# M2Sxxx register map
Vendor: Microsemi; Series: SmartFusion2; File version: 2.0.32
CPU: CM3 r2p1, little endian, MPU, no FPU, 4 interrupt priority bits
Registers are 32-bit, read-write, no defined reset value unless marked. A register's access mark holds for its fields unless they carry their own. Offsets are from the block's base; [hi:lo] are bit positions; {n}, {i} and the like mark numbered series; 'fields as' and 'values as' point back to an identical list.

## USB — No description provided for this peripheral
Base 0x40043000
0x00 USB_FADDR_REG 8-bit — No description provided for this register
  [6:0] FUNC_ADDR — No description provided for this field
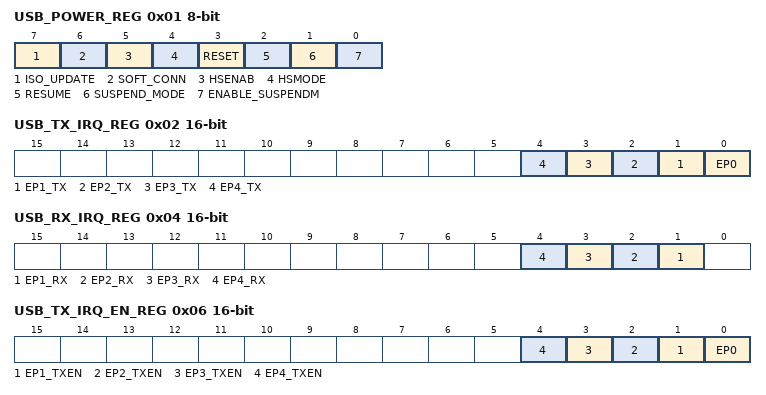
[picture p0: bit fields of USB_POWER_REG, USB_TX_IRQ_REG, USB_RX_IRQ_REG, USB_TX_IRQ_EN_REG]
0x01 USB_POWER_REG 8-bit — No description provided for this register
  [7] ISO_UPDATE ro — No description provided for this field
  [6] SOFT_CONN ro — No description provided for this field
  [5] HSENAB ro — No description provided for this field
  [4] HSMODE ro — No description provided for this field
  [3] RESET ro — No description provided for this field
  [2] RESUME ro — No description provided for this field
  [1] SUSPEND_MODE ro — No description provided for this field
  [0] ENABLE_SUSPENDM ro — No description provided for this field
0x02 USB_TX_IRQ_REG 16-bit — No description provided for this register
  [n] EP{n}_TX ro (n=1..4) — No description provided for this field
  [0] EP0 ro — No description provided for this field
0x04 USB_RX_IRQ_REG 16-bit — No description provided for this register
  [n] EP{n}_RX ro (n=1..4) — No description provided for this field
0x06 USB_TX_IRQ_EN_REG 16-bit — No description provided for this register
  [n] EP{n}_TXEN (n=1..4) — No description provided for this field
  [0] EP0 — No description provided for this field
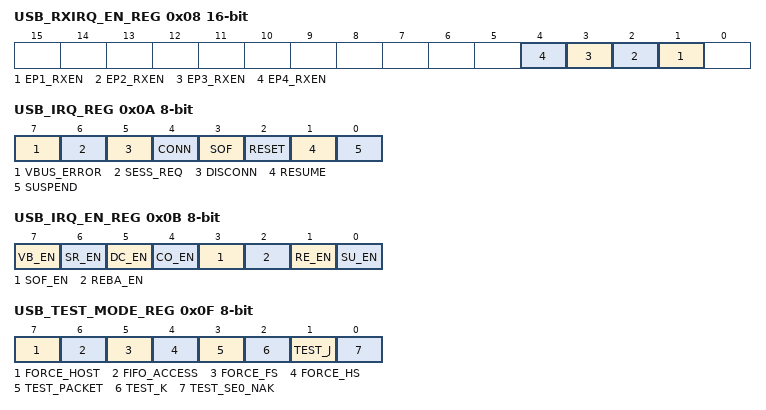
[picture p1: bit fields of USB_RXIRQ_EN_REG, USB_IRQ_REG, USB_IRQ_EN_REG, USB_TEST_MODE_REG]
0x08 USB_RXIRQ_EN_REG 16-bit — No description provided for this register
  [n] EP{n}_RXEN (n=1..4) — No description provided for this field
0x0A USB_IRQ_REG 8-bit — No description provided for this register
  [7] VBUS_ERROR ro — No description provided for this field
  [6] SESS_REQ ro — No description provided for this field
  [5] DISCONN ro — No description provided for this field
  [4] CONN ro — No description provided for this field
  [3] SOF ro — No description provided for this field
  [2] RESET ro — No description provided for this field
  [1] RESUME ro — No description provided for this field
  [0] SUSPEND ro — No description provided for this field
0x0B USB_IRQ_EN_REG 8-bit — No description provided for this register
  [7] VB_EN — No description provided for this field
  [6] SR_EN — No description provided for this field
  [5] DC_EN — No description provided for this field
  [4] CO_EN — No description provided for this field
  [3] SOF_EN — No description provided for this field
  [2] REBA_EN — No description provided for this field
  [1] RE_EN — No description provided for this field
  [0] SU_EN — No description provided for this field
0x0C USB_FRAME_REG 16-bit — No description provided for this register
  [10:0] FRAME_NUMBER ro — No description provided for this field
0x0E USB_INDEX_REG 8-bit — No description provided for this register
  [3:0] SEL_END_POINT — No description provided for this field
0x0F USB_TEST_MODE_REG 8-bit — No description provided for this register
  [7] FORCE_HOST — No description provided for this field
  [6] FIFO_ACCESS — No description provided for this field
  [5] FORCE_FS — No description provided for this field
  [4] FORCE_HS — No description provided for this field
  [3] TEST_PACKET — No description provided for this field
  [2] TEST_K — No description provided for this field
  [1] TEST_J — No description provided for this field
  [0] TEST_SE0_NAK — No description provided for this field
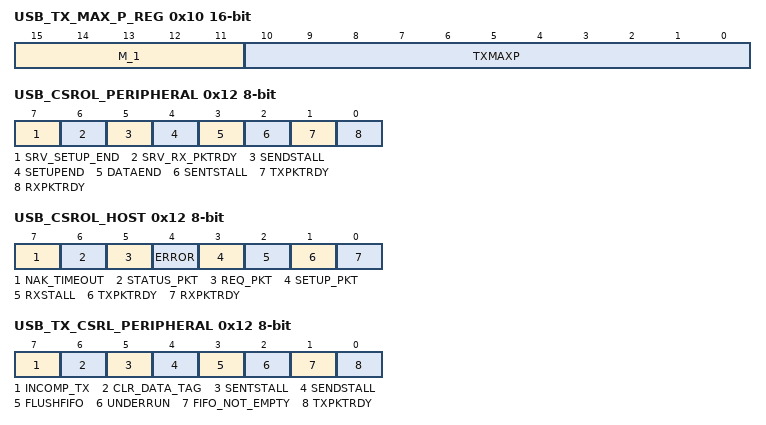
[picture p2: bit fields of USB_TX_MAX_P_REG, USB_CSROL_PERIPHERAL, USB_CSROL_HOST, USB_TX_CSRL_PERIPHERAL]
0x10 USB_TX_MAX_P_REG 16-bit — No description provided for this register
  [15:11] M_1 — No description provided for this field
  [10:0] TXMAXP — No description provided for this field
0x12 USB_CSROL_PERIPHERAL 8-bit — No description provided for this register
  [7] SRV_SETUP_END — No description provided for this field
  [6] SRV_RX_PKTRDY — No description provided for this field
  [5] SENDSTALL — No description provided for this field
  [4] SETUPEND — No description provided for this field
  [3] DATAEND — No description provided for this field
  [2] SENTSTALL — No description provided for this field
  [1] TXPKTRDY — No description provided for this field
  [0] RXPKTRDY — No description provided for this field
0x12 USB_CSROL_HOST 8-bit (alternate view of USB_CSROL_PERIPHERAL) — No description provided for this register
  [7] NAK_TIMEOUT — No description provided for this field
  [6] STATUS_PKT — No description provided for this field
  [5] REQ_PKT — No description provided for this field
  [4] ERROR — No description provided for this field
  [3] SETUP_PKT — No description provided for this field
  [2] RXSTALL — No description provided for this field
  [1] TXPKTRDY — No description provided for this field
  [0] RXPKTRDY — No description provided for this field
0x12 USB_TX_CSRL_PERIPHERAL 8-bit (alternate view of USB_CSROL_PERIPHERAL) — No description provided for this register
  [7] INCOMP_TX — No description provided for this field
  [6] CLR_DATA_TAG — No description provided for this field
  [5] SENTSTALL — No description provided for this field
  [4] SENDSTALL — No description provided for this field
  [3] FLUSHFIFO — No description provided for this field
  [2] UNDERRUN — No description provided for this field
  [1] FIFO_NOT_EMPTY — No description provided for this field
  [0] TXPKTRDY — No description provided for this field
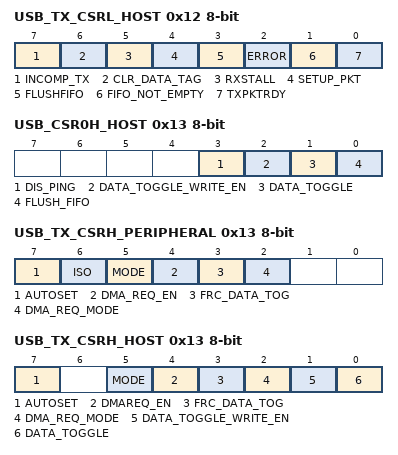
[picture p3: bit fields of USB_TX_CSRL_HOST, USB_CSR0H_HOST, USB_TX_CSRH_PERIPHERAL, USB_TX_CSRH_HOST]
0x12 USB_TX_CSRL_HOST 8-bit (alternate view of USB_CSROL_PERIPHERAL) — No description provided for this register
  [7] INCOMP_TX — No description provided for this field
  [6] CLR_DATA_TAG — No description provided for this field
  [5] RXSTALL — No description provided for this field
  [4] SETUP_PKT — No description provided for this field
  [3] FLUSHFIFO — No description provided for this field
  [2] ERROR — No description provided for this field
  [1] FIFO_NOT_EMPTY — No description provided for this field
  [0] TXPKTRDY — No description provided for this field
0x13 USB_CSR0H_HOST 8-bit — No description provided for this register
  [3] DIS_PING — No description provided for this field
  [2] DATA_TOGGLE_WRITE_EN — No description provided for this field
  [1] DATA_TOGGLE — No description provided for this field
  [0] FLUSH_FIFO — No description provided for this field
0x13 USB_CSROH_PERIPHERAL 8-bit (alternate view of USB_CSR0H_HOST) — No description provided for this register
  [0] FLUSH_FIFO — No description provided for this field
0x13 USB_TX_CSRH_PERIPHERAL 8-bit (alternate view of USB_CSR0H_HOST) — No description provided for this register
  [7] AUTOSET — No description provided for this field
  [6] ISO — No description provided for this field
  [5] MODE — No description provided for this field
  [4] DMA_REQ_EN — No description provided for this field
  [3] FRC_DATA_TOG — No description provided for this field
  [2] DMA_REQ_MODE — No description provided for this field
0x13 USB_TX_CSRH_HOST 8-bit (alternate view of USB_CSR0H_HOST) — No description provided for this register
  [7] AUTOSET — No description provided for this field
  [5] MODE — No description provided for this field
  [4] DMAREQ_EN — No description provided for this field
  [3] FRC_DATA_TOG — No description provided for this field
  [2] DMA_REQ_MODE — No description provided for this field
  [1] DATA_TOGGLE_WRITE_EN — No description provided for this field
  [0] DATA_TOGGLE — No description provided for this field
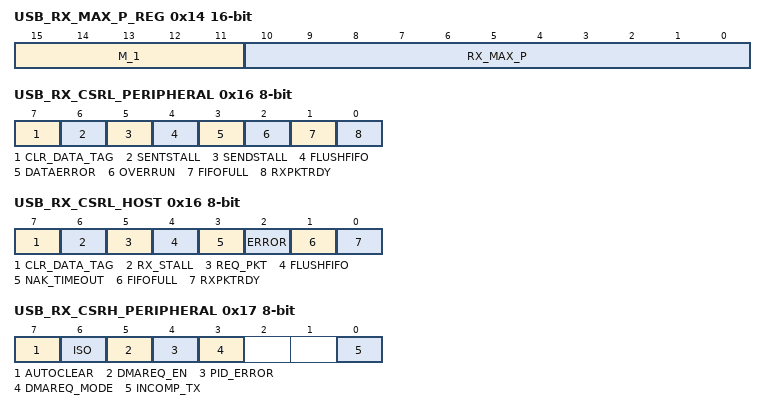
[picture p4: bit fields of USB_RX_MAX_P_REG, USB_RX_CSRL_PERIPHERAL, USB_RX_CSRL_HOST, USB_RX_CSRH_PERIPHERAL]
0x14 USB_RX_MAX_P_REG 16-bit — No description provided for this register
  [15:11] M_1 — No description provided for this field
  [10:0] RX_MAX_P — No description provided for this field
0x16 USB_RX_CSRL_PERIPHERAL 8-bit — No description provided for this register
  [7] CLR_DATA_TAG — No description provided for this field
  [6] SENTSTALL — No description provided for this field
  [5] SENDSTALL — No description provided for this field
  [4] FLUSHFIFO — No description provided for this field
  [3] DATAERROR — No description provided for this field
  [2] OVERRUN — No description provided for this field
  [1] FIFOFULL — No description provided for this field
  [0] RXPKTRDY — No description provided for this field
0x16 USB_RX_CSRL_HOST 8-bit (alternate view of USB_RX_CSRL_PERIPHERAL) — No description provided for this register
  [7] CLR_DATA_TAG — No description provided for this field
  [6] RX_STALL — No description provided for this field
  [5] REQ_PKT — No description provided for this field
  [4] FLUSHFIFO — No description provided for this field
  [3] NAK_TIMEOUT — No description provided for this field
  [2] ERROR — No description provided for this field
  [1] FIFOFULL — No description provided for this field
  [0] RXPKTRDY — No description provided for this field
0x17 USB_RX_CSRH_PERIPHERAL 8-bit — No description provided for this register
  [7] AUTOCLEAR — No description provided for this field
  [6] ISO — No description provided for this field
  [5] DMAREQ_EN — No description provided for this field
  [4] PID_ERROR — No description provided for this field
  [3] DMAREQ_MODE — No description provided for this field
  [0] INCOMP_TX — No description provided for this field
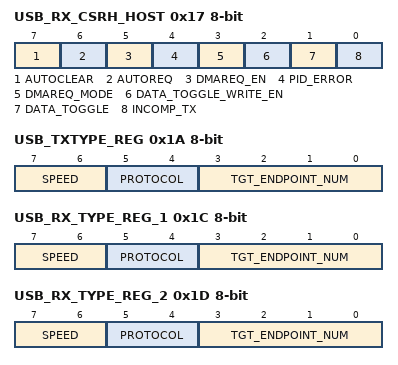
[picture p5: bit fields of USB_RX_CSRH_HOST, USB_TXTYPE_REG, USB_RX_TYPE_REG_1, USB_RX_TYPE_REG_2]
0x17 USB_RX_CSRH_HOST 8-bit (alternate view of USB_RX_CSRH_PERIPHERAL) — No description provided for this register
  [7] AUTOCLEAR — No description provided for this field
  [6] AUTOREQ — No description provided for this field
  [5] DMAREQ_EN — No description provided for this field
  [4] PID_ERROR — No description provided for this field
  [3] DMAREQ_MODE — No description provided for this field
  [2] DATA_TOGGLE_WRITE_EN — No description provided for this field
  [1] DATA_TOGGLE — No description provided for this field
  [0] INCOMP_TX — No description provided for this field
0x18 USB_RX_COUNT_REG 16-bit — No description provided for this register
  [13:0] ENDPOINT_RX_COUNT ro — No description provided for this field
0x18 USB_COUNT0_REG 8-bit (alternate view of USB_RX_COUNT_REG) — No description provided for this register
  [6:0] ENDPOINT_RX_COUNT ro — No description provided for this field
0x1A USB_TYPE0_REG 8-bit — No description provided for this register
  [7:6] SPEED — No description provided for this field
0x1A USB_TXTYPE_REG 8-bit (alternate view of USB_TYPE0_REG) — No description provided for this register
  [7:6] SPEED — No description provided for this field
  [5:4] PROTOCOL — No description provided for this field
  [3:0] TGT_ENDPOINT_NUM — No description provided for this field
0x1B USB_NAK_LIMIT0_REG 8-bit — No description provided for this register
  [4:0] ENDPOINT0_NAK_LIMIT — No description provided for this field
0x1B USB_TX_INTERVAL_REG 8-bit (alternate view of USB_NAK_LIMIT0_REG) — No description provided for this register
  [7:0] TX_INTERVAL — No description provided for this field
0x1C USB_RX_TYPE_REG_1 8-bit — No description provided for this register
  fields as USB_TXTYPE_REG
0x1D USB_RX_TYPE_REG_2 8-bit — No description provided for this register
  fields as USB_TXTYPE_REG
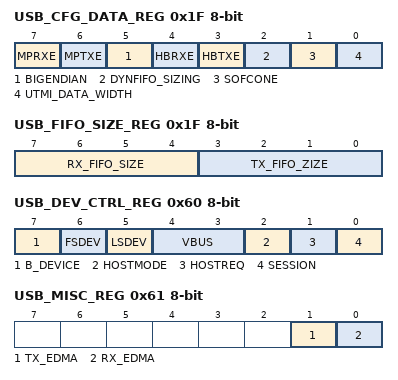
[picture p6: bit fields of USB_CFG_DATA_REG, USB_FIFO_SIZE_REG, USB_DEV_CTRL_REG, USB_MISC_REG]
0x1F USB_CFG_DATA_REG 8-bit — No description provided for this register
  [7] MPRXE ro — No description provided for this field
  [6] MPTXE ro — No description provided for this field
  [5] BIGENDIAN ro — No description provided for this field
  [4] HBRXE ro — No description provided for this field
  [3] HBTXE ro — No description provided for this field
  [2] DYNFIFO_SIZING ro — No description provided for this field
  [1] SOFCONE ro — No description provided for this field
  [0] UTMI_DATA_WIDTH ro — No description provided for this field
0x1F USB_FIFO_SIZE_REG 8-bit (alternate view of USB_CFG_DATA_REG) — No description provided for this register
  [7:4] RX_FIFO_SIZE ro — No description provided for this field
  [3:0] TX_FIFO_ZIZE ro — No description provided for this field
{0x20+4i} USB_EP{i}_FIFO_REG (i=0..4) — No description provided for this register
  [31:0] EP{i}_TXRXDATA_ACC — No description provided for this field
0x60 USB_DEV_CTRL_REG 8-bit — No description provided for this register
  [7] B_DEVICE ro — No description provided for this field
  [6] FSDEV ro — No description provided for this field
  [5] LSDEV ro — No description provided for this field
  [4:3] VBUS ro — No description provided for this field
  [2] HOSTMODE ro — No description provided for this field
  [1] HOSTREQ ro — No description provided for this field
  [0] SESSION ro — No description provided for this field
0x61 USB_MISC_REG 8-bit — No description provided for this register
  [1] TX_EDMA ro — No description provided for this field
  [0] RX_EDMA ro — No description provided for this field
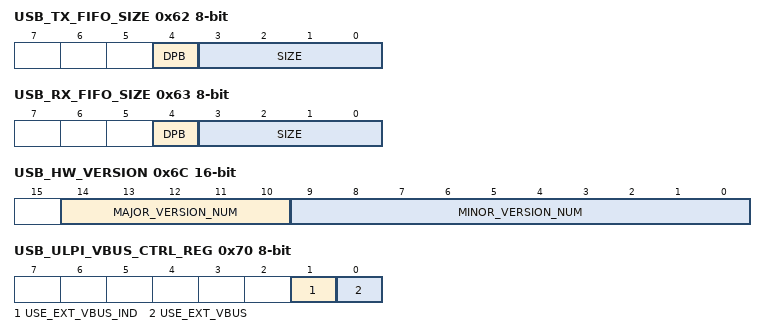
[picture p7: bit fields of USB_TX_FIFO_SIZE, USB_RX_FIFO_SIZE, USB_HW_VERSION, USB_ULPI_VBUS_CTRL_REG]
0x62 USB_TX_FIFO_SIZE 8-bit — No description provided for this register
  [4] DPB — No description provided for this field
  [3:0] SIZE — No description provided for this field
0x63 USB_RX_FIFO_SIZE 8-bit — No description provided for this register
  fields as USB_TX_FIFO_SIZE
0x64 USB_TX_FIFO_ADD_RANGE 16-bit — No description provided for this register
  [12:0] ADDRESS — No description provided for this field
0x66 USB_RX_FIFO_ADD_RANGE 16-bit — No description provided for this register
  [12:0] ADDRESS — No description provided for this field
0x68 USB_VBUS_CSR_REG 8-bit — No description provided for this register
  [3:0] VCONTROL — No description provided for this field
0x6C USB_HW_VERSION 16-bit — No description provided for this register
  [14:10] MAJOR_VERSION_NUM ro — No description provided for this field
  [9:0] MINOR_VERSION_NUM ro — No description provided for this field
0x70 USB_ULPI_VBUS_CTRL_REG 8-bit — No description provided for this register
  [1] USE_EXT_VBUS_IND ro — No description provided for this field
  [0] USE_EXT_VBUS ro — No description provided for this field
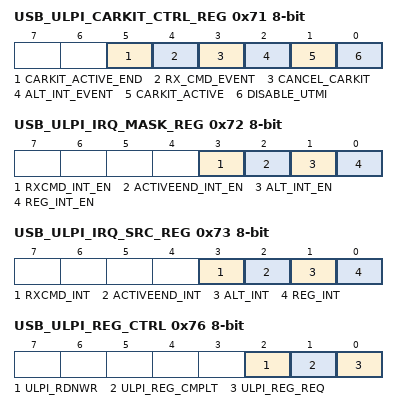
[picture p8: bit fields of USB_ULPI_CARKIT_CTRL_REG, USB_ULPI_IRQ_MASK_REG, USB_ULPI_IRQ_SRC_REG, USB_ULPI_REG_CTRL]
0x71 USB_ULPI_CARKIT_CTRL_REG 8-bit — No description provided for this register
  [5] CARKIT_ACTIVE_END ro — No description provided for this field
  [4] RX_CMD_EVENT ro — No description provided for this field
  [3] CANCEL_CARKIT ro — No description provided for this field
  [2] ALT_INT_EVENT ro — No description provided for this field
  [1] CARKIT_ACTIVE ro — No description provided for this field
  [0] DISABLE_UTMI ro — No description provided for this field
0x72 USB_ULPI_IRQ_MASK_REG 8-bit — No description provided for this register
  [3] RXCMD_INT_EN ro — No description provided for this field
  [2] ACTIVEEND_INT_EN ro — No description provided for this field
  [1] ALT_INT_EN ro — No description provided for this field
  [0] REG_INT_EN ro — No description provided for this field
0x73 USB_ULPI_IRQ_SRC_REG 8-bit — No description provided for this register
  [3] RXCMD_INT ro — No description provided for this field
  [2] ACTIVEEND_INT ro — No description provided for this field
  [1] ALT_INT ro — No description provided for this field
  [0] REG_INT ro — No description provided for this field
0x74 USB_ULPI_DATA_REG 8-bit — No description provided for this register
  [7:0] ULPI_REG_DATA ro — No description provided for this field
0x75 USB_ULPI_ADDR_RANGE 8-bit — No description provided for this register
  [7:0] ULPI_REG_ADDR ro — No description provided for this field
0x76 USB_ULPI_REG_CTRL 8-bit — No description provided for this register
  [2] ULPI_RDNWR ro — No description provided for this field
  [1] ULPI_REG_CMPLT ro — No description provided for this field
  [0] ULPI_REG_REQ ro — No description provided for this field
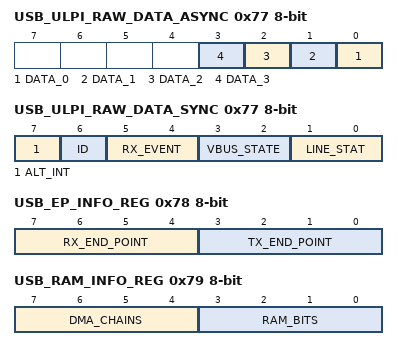
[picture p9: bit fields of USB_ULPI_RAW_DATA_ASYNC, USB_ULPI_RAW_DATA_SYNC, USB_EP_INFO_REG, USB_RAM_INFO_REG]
0x77 USB_ULPI_RAW_DATA_ASYNC 8-bit — No description provided for this register
  [n] DATA_{n} ro (n=0..3) — No description provided for this field
0x77 USB_ULPI_RAW_DATA_SYNC 8-bit (alternate view of USB_ULPI_RAW_DATA_ASYNC) — No description provided for this register
  [7] ALT_INT ro — No description provided for this field
  [6] ID ro — No description provided for this field
  [5:4] RX_EVENT ro — No description provided for this field
  [3:2] VBUS_STATE ro — No description provided for this field
  [1:0] LINE_STAT ro — No description provided for this field
0x78 USB_EP_INFO_REG 8-bit — No description provided for this register
  [7:4] RX_END_POINT ro — No description provided for this field
  [3:0] TX_END_POINT ro — No description provided for this field
0x79 USB_RAM_INFO_REG 8-bit — No description provided for this register
  [7:4] DMA_CHAINS ro — No description provided for this field
  [3:0] RAM_BITS ro — No description provided for this field
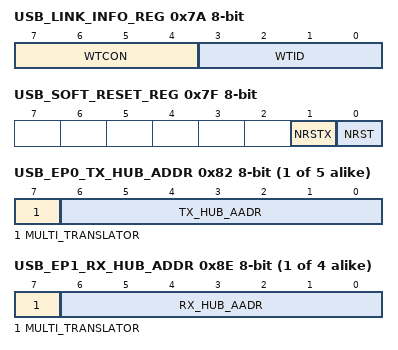
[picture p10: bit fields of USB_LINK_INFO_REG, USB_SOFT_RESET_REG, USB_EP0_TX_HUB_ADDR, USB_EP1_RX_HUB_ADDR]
0x7A USB_LINK_INFO_REG 8-bit — No description provided for this register
  [7:4] WTCON — No description provided for this field
  [3:0] WTID — No description provided for this field
0x7B USB_VP_LEN_REG 8-bit — No description provided for this register
  [7:0] VPLEN — No description provided for this field
0x7C USB_HS_EOF1_REG 8-bit — No description provided for this register
  [7:0] HS_EOF1 — No description provided for this field
0x7D USB_FS_EOF1_REG 8-bit — No description provided for this register
  [7:0] FS_EOF1 — No description provided for this field
0x7E USB_LS_EOF1_REG 8-bit — No description provided for this register
  [7:0] LS_EOF1 — No description provided for this field
0x7F USB_SOFT_RESET_REG 8-bit — No description provided for this register
  [1] NRSTX — No description provided for this field
  [0] NRST — No description provided for this field
{0x80+8i} USB_EP{i}_TX_FUNC_ADDR 8-bit (i=0..4) — No description provided for this register
  [6:0] TX_FUNC_ADDR — No description provided for this field
{0x82+8i} USB_EP{i}_TX_HUB_ADDR 8-bit (i=0..4) — No description provided for this register
  [7] MULTI_TRANSLATOR — No description provided for this field
  [6:0] TX_HUB_AADR — No description provided for this field
{0x83+8i} USB_EP{i}_TX_HUB_PORT 8-bit (i=0..4) — No description provided for this register
  [6:0] TX_HUB_PORT — No description provided for this field
{0x86+8i} USB_EP{i}_RX_HUB_ADDR 8-bit (i=1..4) — No description provided for this register
  [7] MULTI_TRANSLATOR — No description provided for this field
  [6:0] RX_HUB_AADR — No description provided for this field
{0x87+8i} USB_EP{i}_RX_HUB_PORT 8-bit (i=1..4) — No description provided for this register
  [6:0] RX_HUB_PORT — No description provided for this field
{0x84+8i} USB_EP{i}_RX_FUNC_ADDR 8-bit (i=2..4) — No description provided for this register
  [6:0] RX_FUNC_ADDR — No description provided for this field
0x100 USB_EP0_TX_MAX_P 16-bit — No description provided for this register
  [10:0] EP0_TX_MAP — No description provided for this field
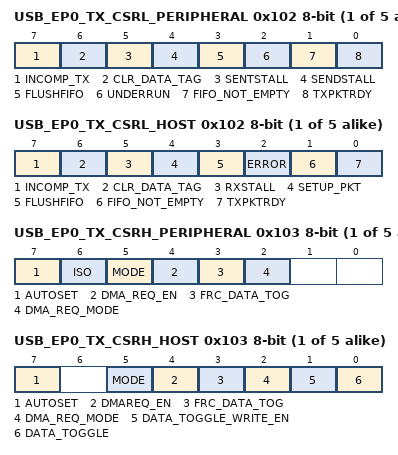
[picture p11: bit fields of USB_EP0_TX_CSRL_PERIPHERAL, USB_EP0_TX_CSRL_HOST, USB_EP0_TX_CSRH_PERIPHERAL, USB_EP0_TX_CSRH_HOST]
{0x102+0x10*i} USB_EP{i}_TX_CSRL_PERIPHERAL 8-bit (i=0..4) — No description provided for this register
  fields as USB_TX_CSRL_PERIPHERAL
{0x102+0x10*i} USB_EP{i}_TX_CSRL_HOST 8-bit (alternate view of USB_EP{i}_TX_CSRL_PERIPHERAL) (i=0..4) — No description provided for this register
  fields as USB_TX_CSRL_HOST
{0x103+0x10*i} USB_EP{i}_TX_CSRH_PERIPHERAL 8-bit (i=0..4) — No description provided for this register
  fields as USB_TX_CSRH_PERIPHERAL
{0x103+0x10*i} USB_EP{i}_TX_CSRH_HOST 8-bit (alternate view of USB_EP{i}_TX_CSRH_PERIPHERAL) (i=0..4) — No description provided for this register
  fields as USB_TX_CSRH_HOST
{0x104+0x10*i} USB_EP{i}_RX_MAX_P 16-bit (i=0..4) — No description provided for this register
  [10:0] EP{i}_RX_MAX_P — No description provided for this field
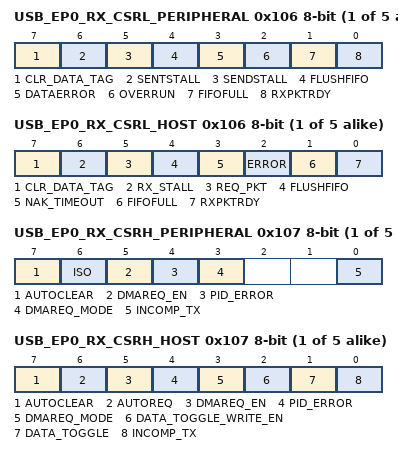
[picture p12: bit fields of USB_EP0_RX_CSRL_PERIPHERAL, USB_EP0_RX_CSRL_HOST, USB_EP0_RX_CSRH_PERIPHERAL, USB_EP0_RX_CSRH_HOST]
{0x106+0x10*i} USB_EP{i}_RX_CSRL_PERIPHERAL 8-bit (i=0..4) — No description provided for this register
  fields as USB_RX_CSRL_PERIPHERAL
{0x106+0x10*i} USB_EP{i}_RX_CSRL_HOST 8-bit (alternate view of USB_EP{i}_RX_CSRL_PERIPHERAL) (i=0..4) — No description provided for this register
  fields as USB_RX_CSRL_HOST
{0x107+0x10*i} USB_EP{i}_RX_CSRH_PERIPHERAL 8-bit (i=0..4) — No description provided for this register
  fields as USB_RX_CSRH_PERIPHERAL
{0x107+0x10*i} USB_EP{i}_RX_CSRH_HOST 8-bit (alternate view of USB_EP{i}_RX_CSRH_PERIPHERAL) (i=0..4) — No description provided for this register
  fields as USB_RX_CSRH_HOST
{0x108+0x10*i} USB_EP{i}_RX_COUNT 16-bit (i=0..4) — No description provided for this register
  [13:0] EP{i}_RX_COUNT ro — No description provided for this field
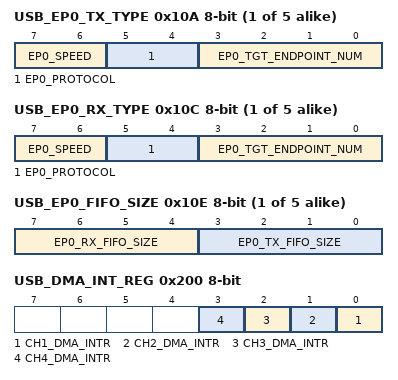
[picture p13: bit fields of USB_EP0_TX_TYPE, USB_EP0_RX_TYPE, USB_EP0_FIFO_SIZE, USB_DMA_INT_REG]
{0x10A+0x10*i} USB_EP{i}_TX_TYPE 8-bit (i=0..4) — No description provided for this register
  [7:6] EP{i}_SPEED wo — No description provided for this field
  [5:4] EP{i}_PROTOCOL wo — No description provided for this field
  [3:0] EP{i}_TGT_ENDPOINT_NUM wo — No description provided for this field
{0x10B+0x10*i} USB_EP{i}_TX_INTERVAL 8-bit (i=0..4) — No description provided for this register
  [7:0] EP{i}_TX_INTERVAL — No description provided for this field
{0x10C+0x10*i} USB_EP{i}_RX_TYPE 8-bit (i=0..4) — No description provided for this register
  [7:6] EP{i}_SPEED — No description provided for this field
  [5:4] EP{i}_PROTOCOL — No description provided for this field
  [3:0] EP{i}_TGT_ENDPOINT_NUM — No description provided for this field
{0x10D+0x10*i} USB_EP{i}_RX_INTERVAL 8-bit (i=0..4) — No description provided for this register
  [7:0] EP{i}_RX_INTERVAL — No description provided for this field
{0x10E+0x10*i} USB_EP{i}_FIFO_SIZE 8-bit (i=0..4) — No description provided for this register
  [7:4] EP{i}_RX_FIFO_SIZE ro — No description provided for this field
  [3:0] EP{i}_TX_FIFO_SIZE ro — No description provided for this field
{0x100+0x10*i} USB_EP{i}_TX_MAX_P 16-bit (i=1..4) — No description provided for this register
  [10:0] EP{i}_TX_MAP ro — No description provided for this field
0x200 USB_DMA_INT_REG 8-bit — No description provided for this register
  [n-1] CH{n}_DMA_INTR ro (n=1..4) — No description provided for this field
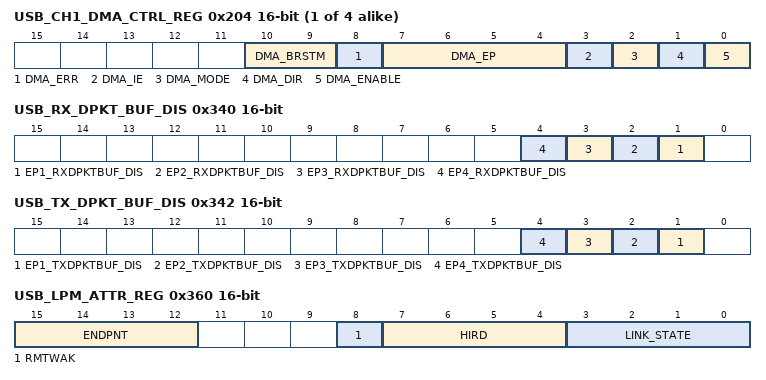
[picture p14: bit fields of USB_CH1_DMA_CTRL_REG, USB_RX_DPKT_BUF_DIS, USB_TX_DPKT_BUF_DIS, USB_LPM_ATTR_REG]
{0x1F4+0x10*i} USB_CH{i}_DMA_CTRL_REG 16-bit (i=1..4) — No description provided for this register
  [10:9] DMA_BRSTM — No description provided for this field
  [8] DMA_ERR — No description provided for this field
  [7:4] DMA_EP — No description provided for this field
  [3] DMA_IE — No description provided for this field
  [2] DMA_MODE — No description provided for this field
  [1] DMA_DIR — No description provided for this field
  [0] DMA_ENABLE — No description provided for this field
{0x1F8+0x10*i} USB_CH{i}_DMA_ADDR_REG (i=1..4) — No description provided for this register
  [31:0] DMA_ADDR — No description provided for this field
{0x1FC+0x10*i} USB_CH{i}_DMA_COUNT_REG (i=1..4) — No description provided for this register
  [31:0] DMA_COUNT — No description provided for this field
{0x300+4i} USB_EP{i}_REQ_PKT_COUNT 16-bit (i=0..4) — No description provided for this register
  [15:0] EP{i}_REQ_PKT_COUNT — No description provided for this field
0x340 USB_RX_DPKT_BUF_DIS 16-bit — No description provided for this register
  [n] EP{n}_RXDPKTBUF_DIS (n=1..4) — No description provided for this field
0x342 USB_TX_DPKT_BUF_DIS 16-bit — No description provided for this register
  [n] EP{n}_TXDPKTBUF_DIS (n=1..4) — No description provided for this field
0x344 USB_C_T_UCH 16-bit — No description provided for this register
  [15:0] C_T_UCH — No description provided for this field
0x346 USB_C_T_HHSRTN_REG 16-bit — No description provided for this register
  [15:0] C_T_HHSRTN — No description provided for this field
0x348 USB_C_T_HSBT_REG 8-bit — No description provided for this register
  [3:0] HS_TIMEOUT_ADDR — No description provided for this field
0x360 USB_LPM_ATTR_REG 16-bit — No description provided for this register
  [15:12] ENDPNT ro — No description provided for this field
  [8] RMTWAK ro — No description provided for this field
  [7:4] HIRD ro — No description provided for this field
  [3:0] LINK_STATE ro — No description provided for this field
0x362 USB_LPM_CTRL_PERIPHERAL 8-bit — No description provided for this register
  [4] LPMNAK ro — No description provided for this field
  [3:2] LPMEN ro — No description provided for this field
  [1] LPMRES ro — No description provided for this field
  [0] LPMXMT ro — No description provided for this field
0x362 USB_LPM_CTRL_HOST 8-bit (alternate view of USB_LPM_CTRL_PERIPHERAL) — No description provided for this register
  [1] LPMRES ro — No description provided for this field
  [0] LPMXMT ro — No description provided for this field
0x363 USB_LPM_INTR_EN 8-bit — No description provided for this register
  [5] LPMERREN ro — No description provided for this field
  [4] LPMRESEN ro — No description provided for this field
  [3] LPMNCEN ro — No description provided for this field
  [2] LPMACKEN ro — No description provided for this field
  [1] LPMNYEN ro — No description provided for this field
  [0] LPMSTEN ro — No description provided for this field
0x364 USB_LPM_INTR_PERIPHERAL 8-bit — No description provided for this register
  [5] LPMERR ro — No description provided for this field
  [4] LPMRES ro — No description provided for this field
  [3] LPMNC ro — No description provided for this field
  [2] LPMACK ro — No description provided for this field
  [1] LPMNY ro — No description provided for this field
  [0] LPMST ro — No description provided for this field
0x364 USB_LPM_INTR_HOST 8-bit (alternate view of USB_LPM_INTR_PERIPHERAL) — No description provided for this register
  fields as USB_LPM_INTR_PERIPHERAL
0x365 USB_LPM_FADDR 8-bit — No description provided for this register
  [6:0] LPMFADDR ro — No description provided for this field
